VERSION ""

NS_ :

BU_: EBCM EON CAM RADAR PCM EPS VSA SCM BDY XXX EPB

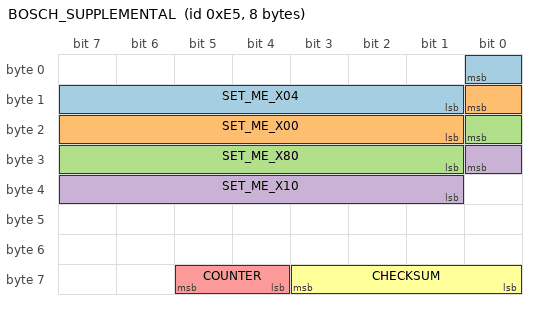
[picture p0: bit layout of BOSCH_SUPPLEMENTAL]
BO_ 229 BOSCH_SUPPLEMENTAL: 8 XXX
 SG_ SET_ME_X04 : 0|8@0+ (1,0) [0|255] "" XXX
 SG_ SET_ME_X00 : 8|8@0+ (1,0) [0|255] "" XXX
 SG_ SET_ME_X80 : 16|8@0+ (1,0) [0|255] "" XXX
 SG_ SET_ME_X10 : 24|8@0+ (1,0) [0|255] "" XXX
 SG_ COUNTER : 61|2@0+ (1,0) [0|3] "" XXX
 SG_ CHECKSUM : 59|4@0+ (1,0) [0|15] "" XXX

BO_ 513 SOMETHING: 8 XXX
 SG_ FULL : 7|63@0+ (1,0) [0|268435455] "" XXX

BO_ 576 CUR_LANE_LEFT_1: 8 XXX
 SG_ FULL : 7|63@0+ (1,0) [0|268435455] "" XXX
 SG_ PARM_1 : 6|11@0- (1,0) [-1023|1023] "" XXX
 SG_ PARM_2 : 22|11@0- (1,0) [-1023|1023] "" XXX
 SG_ PARM_3 : 39|9@0+ (1,0) [0|511] "" XXX
 SG_ PARM_4 : 46|7@0+ (1,0) [0|127] "" XXX
 SG_ PARM_5 : 54|7@0+ (1,0) [0|127] "" XXX
 SG_ FRAME_ID : 11|4@0+ (1,0) [0|15] "" XXX

BO_ 577 CUR_LANE_LEFT_2: 8 XXX
 SG_ FULL : 7|63@0+ (1,0) [0|268435455] "" XXX
 SG_ PARM_6 : 3|8@0+ (1,0) [0|255] "" XXX
 SG_ PARM_7 : 22|11@0- (1,0) [-1023|1023] "" XXX
 SG_ PARM_8 : 24|4@0+ (1,0) [0|15] "" XXX
 SG_ PARM_11 : 27|4@0+ (1,0) [0|15] "" XXX
 SG_ PARM_12 : 12|4@0+ (1,0) [0|15] "" XXX
 SG_ PARM_13 : 40|4@0+ (1,0) [0|15] "" XXX
 SG_ PARM_9 : 38|11@0- (1,0) [-1023|1023] "" XXX
 SG_ PARM_10 : 54|7@0- (1,0) [-63|63] "" XXX
 SG_ DASHED_LINE : 14|1@0+ (1,0) [0|1] "" XXX
 SG_ SOLID_LINE : 13|1@0+ (1,0) [0|1] "" XXX
 SG_ FRAME_ID : 7|4@0+ (1,0) [0|15] "" XXX

BO_ 579 CUR_LANE_RIGHT_1: 8 XXX
 SG_ FULL : 7|63@0+ (1,0) [0|268435455] "" XXX
 SG_ PARM_1 : 6|11@0- (1,0) [-1023|1023] "" XXX
 SG_ PARM_2 : 22|11@0- (1,0) [-1023|1023] "" XXX
 SG_ PARM_3 : 39|9@0+ (1,0) [0|511] "" XXX
 SG_ PARM_4 : 46|7@0+ (1,0) [0|127] "" XXX
 SG_ PARM_5 : 54|7@0+ (1,0) [0|127] "" XXX
 SG_ FRAME_ID : 11|4@0+ (1,0) [0|15] "" XXX

BO_ 580 CUR_LANE_RIGHT_2: 8 XXX
 SG_ FULL : 7|63@0+ (1,0) [0|268435455] "" XXX
 SG_ PARM_6 : 3|8@0+ (1,0) [0|255] "" XXX
 SG_ PARM_7 : 22|11@0- (1,0) [-1023|1023] "" XXX
 SG_ PARM_8 : 24|4@0+ (1,0) [0|15] "" XXX
 SG_ PARM_11 : 27|4@0+ (1,0) [0|15] "" XXX
 SG_ PARM_12 : 12|4@0+ (1,0) [0|15] "" XXX
 SG_ PARM_13 : 40|4@0+ (1,0) [0|15] "" XXX
 SG_ PARM_9 : 38|11@0- (1,0) [-1023|1023] "" XXX
 SG_ PARM_10 : 54|7@0- (1,0) [-63|63] "" XXX
 SG_ DASHED_LINE : 14|1@0+ (1,0) [0|1] "" XXX
 SG_ SOLID_LINE : 13|1@0+ (1,0) [0|1] "" XXX
 SG_ FRAME_ID : 7|4@0+ (1,0) [0|15] "" XXX

BO_ 582 ADJ_LANE_LEFT_1: 8 XXX
 SG_ FULL : 7|63@0+ (1,0) [0|268435455] "" XXX
 SG_ PARM_1 : 6|11@0- (1,0) [-1023|1023] "" XXX
 SG_ PARM_2 : 22|11@0- (1,0) [-1023|1023] "" XXX
 SG_ PARM_3 : 39|9@0+ (1,0) [0|511] "" XXX
 SG_ PARM_4 : 46|7@0+ (1,0) [0|127] "" XXX
 SG_ PARM_5 : 54|7@0+ (1,0) [0|127] "" XXX
 SG_ FRAME_ID : 11|4@0+ (1,0) [0|15] "" XXX

BO_ 583 ADJ_LANE_LEFT_2: 8 XXX
 SG_ FULL : 7|63@0+ (1,0) [0|268435455] "" XXX
 SG_ PARM_6 : 3|8@0+ (1,0) [0|255] "" XXX
 SG_ PARM_7 : 22|11@0- (1,0) [-1023|1023] "" XXX
 SG_ PARM_8 : 24|4@0+ (1,0) [0|15] "" XXX
 SG_ PARM_11 : 27|4@0+ (1,0) [0|15] "" XXX
 SG_ PARM_12 : 12|4@0+ (1,0) [0|15] "" XXX
 SG_ PARM_13 : 40|4@0+ (1,0) [0|15] "" XXX
 SG_ PARM_9 : 38|11@0- (1,0) [-1023|1023] "" XXX
 SG_ PARM_10 : 54|7@0- (1,0) [-63|63] "" XXX
 SG_ DASHED_LINE : 14|1@0+ (1,0) [0|1] "" XXX
 SG_ SOLID_LINE : 13|1@0+ (1,0) [0|1] "" XXX
 SG_ FRAME_ID : 7|4@0+ (1,0) [0|15] "" XXX

BO_ 585 ADJ_LANE_RIGHT_1: 8 XXX
 SG_ FULL : 7|63@0+ (1,0) [0|268435455] "" XXX
 SG_ PARM_1 : 6|11@0- (1,0) [-1023|1023] "" XXX
 SG_ PARM_2 : 22|11@0- (1,0) [-1023|1023] "" XXX
 SG_ PARM_3 : 39|9@0+ (1,0) [0|511] "" XXX
 SG_ PARM_4 : 46|7@0+ (1,0) [0|127] "" XXX
 SG_ PARM_5 : 54|7@0+ (1,0) [0|127] "" XXX
 SG_ FRAME_ID : 11|4@0+ (1,0) [0|15] "" XXX

BO_ 586 ADJ_LANE_RIGHT_2: 8 XXX
 SG_ FULL : 7|63@0+ (1,0) [0|268435455] "" XXX
 SG_ PARM_6 : 3|8@0+ (1,0) [0|255] "" XXX
 SG_ PARM_7 : 22|11@0- (1,0) [-1023|1023] "" XXX
 SG_ PARM_8 : 24|4@0+ (1,0) [0|15] "" XXX
 SG_ PARM_11 : 27|4@0+ (1,0) [0|15] "" XXX
 SG_ PARM_12 : 12|4@0+ (1,0) [0|15] "" XXX
 SG_ PARM_13 : 40|4@0+ (1,0) [0|15] "" XXX
 SG_ PARM_9 : 38|11@0- (1,0) [-1023|1023] "" XXX
 SG_ PARM_10 : 54|7@0- (1,0) [-63|63] "" XXX
 SG_ DASHED_LINE : 14|1@0+ (1,0) [0|1] "" XXX
 SG_ SOLID_LINE : 13|1@0+ (1,0) [0|1] "" XXX
 SG_ FRAME_ID : 7|4@0+ (1,0) [0|15] "" XXX

BO_ 640 OBJECT_A1: 8 XXX
 SG_ FULL : 7|63@0+ (1,0) [0|268435455] "" XXX
 SG_ CHECKSUM : 56|4@1+ (1,0) [0|15] "" XXX
 SG_ COUNTER : 60|2@1+ (1,0) [0|15] "" XXX
 SG_ CLOSING_SPEED : 6|7@0- (1,0) [-127|127] "" XXX
 SG_ PARM_1 : 15|8@0+ (1,0) [0|1] "" XXX
 SG_ DISTANCE : 22|11@0+ (1,0) [0|8191] "" XXX
 SG_ FRAME_ID : 27|4@0+ (1,0) [0|1] "" XXX
 SG_ OFFSET : 38|10@0- (1,0) [-1023|1023] "" XXX
 SG_ PARM_2 : 44|15@0+ (1,0) [0|31] "" XXX

BO_ 641 OBJECT_A2: 8 XXX
 SG_ FULL : 7|63@0+ (1,0) [0|268435455] "" XXX

BO_ 642 OBJECT_A3: 8 XXX
 SG_ FULL : 7|63@0+ (1,0) [0|268435455] "" XXX

BO_ 643 OBJECT_A4: 8 XXX
 SG_ FULL : 7|63@0+ (1,0) [0|268435455] "" XXX

BO_ 644 OBJECT_A5: 8 XXX
 SG_ FULL : 7|63@0+ (1,0) [0|268435455] "" XXX

BO_ 645 OBJECT_A6: 8 XXX
 SG_ FULL : 7|63@0+ (1,0) [0|268435455] "" XXX

BO_ 646 OBJECT_A7: 8 XXX
 SG_ FULL : 7|63@0+ (1,0) [0|268435455] "" XXX

BO_ 647 OBJECT_A8: 8 XXX
 SG_ FULL : 7|63@0+ (1,0) [0|268435455] "" XXX

BO_ 648 OBJECT_A9: 8 XXX
 SG_ FULL : 7|63@0+ (1,0) [0|268435455] "" XXX

BO_ 649 OBJECT_A10: 8 XXX
 SG_ FULL : 7|63@0+ (1,0) [0|268435455] "" XXX

BO_ 650 OBJECT_A11: 8 XXX
 SG_ FULL : 7|63@0+ (1,0) [0|268435455] "" XXX

BO_ 651 OBJECT_A12: 8 XXX
 SG_ FULL : 7|63@0+ (1,0) [0|268435455] "" XXX

BO_ 652 OBJECT_A13: 8 XXX
 SG_ FULL : 7|63@0+ (1,0) [0|268435455] "" XXX

BO_ 653 OBJECT_A14: 8 XXX
 SG_ FULL : 7|63@0+ (1,0) [0|268435455] "" XXX

BO_ 654 OBJECT_A15: 8 XXX
 SG_ FULL : 7|63@0+ (1,0) [0|268435455] "" XXX

BO_ 655 OBJECT_A16: 8 XXX
 SG_ FULL : 7|63@0+ (1,0) [0|268435455] "" XXX

BO_ 656 OBJECT_A17: 8 XXX
 SG_ FULL : 7|63@0+ (1,0) [0|268435455] "" XXX

BO_ 657 OBJECT_A18: 8 XXX
 SG_ FULL : 7|63@0+ (1,0) [0|268435455] "" XXX

BO_ 658 OBJECT_A19: 8 XXX
 SG_ FULL : 7|63@0+ (1,0) [0|268435455] "" XXX

BO_ 659 OBJECT_A20: 8 XXX
 SG_ FULL : 7|63@0+ (1,0) [0|268435455] "" XXX

BO_ 660 OBJECT_A21: 8 XXX
 SG_ FULL : 7|63@0+ (1,0) [0|268435455] "" XXX

BO_ 661 OBJECT_A22: 8 XXX
 SG_ FULL : 7|63@0+ (1,0) [0|268435455] "" XXX

BO_ 662 OBJECT_A23: 8 XXX
 SG_ FULL : 7|63@0+ (1,0) [0|268435455] "" XXX

BO_ 663 OBJECT_A24: 8 XXX
 SG_ FULL : 7|63@0+ (1,0) [0|268435455] "" XXX

BO_ 712 OBJECT_B1: 8 XXX
 SG_ FULL : 7|63@0+ (1,0) [0|268435455] "" XXX

BO_ 713 OBJECT_B2: 8 XXX
 SG_ FULL : 7|63@0+ (1,0) [0|268435455] "" XXX

BO_ 714 OBJECT_B3: 8 XXX
 SG_ FULL : 7|63@0+ (1,0) [0|268435455] "" XXX

BO_ 715 OBJECT_B4: 8 XXX
 SG_ FULL : 7|63@0+ (1,0) [0|268435455] "" XXX

BO_ 716 OBJECT_B5: 8 XXX
 SG_ FULL : 7|63@0+ (1,0) [0|268435455] "" XXX

BO_ 717 OBJECT_B6: 8 XXX
 SG_ FULL : 7|63@0+ (1,0) [0|268435455] "" XXX

BO_ 718 OBJECT_B7: 8 XXX
 SG_ FULL : 7|63@0+ (1,0) [0|268435455] "" XXX

BO_ 719 OBJECT_B8: 8 XXX
 SG_ FULL : 7|63@0+ (1,0) [0|268435455] "" XXX

BO_ 720 OBJECT_B9: 8 XXX
 SG_ FULL : 7|63@0+ (1,0) [0|268435455] "" XXX

BO_ 721 OBJECT_B10: 8 XXX
 SG_ FULL : 7|63@0+ (1,0) [0|268435455] "" XXX

BO_ 722 OBJECT_B11: 8 XXX
 SG_ FULL : 7|63@0+ (1,0) [0|268435455] "" XXX

BO_ 723 OBJECT_B12: 8 XXX
 SG_ FULL : 7|63@0+ (1,0) [0|268435455] "" XXX

BO_ 724 OBJECT_B13: 8 XXX
 SG_ FULL : 7|63@0+ (1,0) [0|268435455] "" XXX

BO_ 725 OBJECT_B14: 8 XXX
 SG_ FULL : 7|63@0+ (1,0) [0|268435455] "" XXX

BO_ 726 OBJECT_B15: 8 XXX
 SG_ FULL : 7|63@0+ (1,0) [0|268435455] "" XXX

BO_ 727 OBJECT_B16: 8 XXX
 SG_ FULL : 7|63@0+ (1,0) [0|268435455] "" XXX

BO_ 728 OBJECT_B17: 8 XXX
 SG_ FULL : 7|63@0+ (1,0) [0|268435455] "" XXX

BO_ 729 OBJECT_B18: 8 XXX
 SG_ FULL : 7|63@0+ (1,0) [0|268435455] "" XXX

BO_ 730 OBJECT_B19: 8 XXX
 SG_ FULL : 7|63@0+ (1,0) [0|268435455] "" XXX

BO_ 731 OBJECT_B20: 8 XXX
 SG_ FULL : 7|63@0+ (1,0) [0|268435455] "" XXX

BO_ 732 OBJECT_B21: 8 XXX
 SG_ FULL : 7|63@0+ (1,0) [0|268435455] "" XXX

BO_ 733 OBJECT_B22: 8 XXX
 SG_ FULL : 7|63@0+ (1,0) [0|268435455] "" XXX

BO_ 734 OBJECT_B23: 8 XXX
 SG_ FULL : 7|63@0+ (1,0) [0|268435455] "" XXX

BO_ 735 OBJECT_B24: 8 XXX
 SG_ FULL : 7|63@0+ (1,0) [0|268435455] "" XXX

BO_ 736 OBJECT_B25: 8 XXX
 SG_ FULL : 7|63@0+ (1,0) [0|268435455] "" XXX

BO_ 737 OBJECT_B26: 8 XXX
 SG_ FULL : 7|63@0+ (1,0) [0|268435455] "" XXX

BO_ 738 OBJECT_B27: 8 XXX
 SG_ FULL : 7|63@0+ (1,0) [0|268435455] "" XXX

BO_ 739 OBJECT_B28: 8 XXX
 SG_ FULL : 7|63@0+ (1,0) [0|268435455] "" XXX

BO_ 740 OBJECT_B29: 8 XXX
 SG_ FULL : 7|63@0+ (1,0) [0|268435455] "" XXX

BO_ 741 OBJECT_B30: 8 XXX
 SG_ FULL : 7|63@0+ (1,0) [0|268435455] "" XXX

BO_ 742 OBJECT_B31: 8 XXX
 SG_ FULL : 7|63@0+ (1,0) [0|268435455] "" XXX

BO_ 743 OBJECT_B32: 8 XXX
 SG_ FULL : 7|63@0+ (1,0) [0|268435455] "" XXX

BO_ 744 OBJECT_B33: 8 XXX
 SG_ FULL : 7|63@0+ (1,0) [0|268435455] "" XXX

BO_ 745 OBJECT_B34: 8 XXX
 SG_ FULL : 7|63@0+ (1,0) [0|268435455] "" XXX

BO_ 746 OBJECT_B35: 8 XXX
 SG_ FULL : 7|63@0+ (1,0) [0|268435455] "" XXX

BO_ 747 OBJECT_B36: 8 XXX
 SG_ FULL : 7|63@0+ (1,0) [0|268435455] "" XXX

BO_ 748 OBJECT_B37: 8 XXX
 SG_ FULL : 7|63@0+ (1,0) [0|268435455] "" XXX

BO_ 749 OBJECT_B38: 8 XXX
 SG_ FULL : 7|63@0+ (1,0) [0|268435455] "" XXX

BO_ 750 OBJECT_B39: 8 XXX
 SG_ FULL : 7|63@0+ (1,0) [0|268435455] "" XXX

BO_ 751 OBJECT_B40: 8 XXX
 SG_ FULL : 7|63@0+ (1,0) [0|268435455] "" XXX

BO_ 752 OBJECT_B41: 8 XXX
 SG_ FULL : 7|63@0+ (1,0) [0|268435455] "" XXX

BO_ 753 OBJECT_B42: 8 XXX
 SG_ FULL : 7|63@0+ (1,0) [0|268435455] "" XXX

BO_ 754 OBJECT_B43: 8 XXX
 SG_ FULL : 7|63@0+ (1,0) [0|268435455] "" XXX

BO_ 755 OBJECT_B44: 8 XXX
 SG_ FULL : 7|63@0+ (1,0) [0|268435455] "" XXX

BO_ 756 OBJECT_B45: 8 XXX
 SG_ FULL : 7|63@0+ (1,0) [0|268435455] "" XXX

BO_ 757 OBJECT_B46: 8 XXX
 SG_ FULL : 7|63@0+ (1,0) [0|268435455] "" XXX

BO_ 758 OBJECT_B47: 8 XXX
 SG_ FULL : 7|63@0+ (1,0) [0|268435455] "" XXX

BO_ 759 OBJECT_B48: 8 XXX
 SG_ FULL : 7|63@0+ (1,0) [0|268435455] "" XXX

BO_ 760 OBJECT_B49: 8 XXX
 SG_ FULL : 7|63@0+ (1,0) [0|268435455] "" XXX

BO_ 761 OBJECT_B50: 8 XXX
 SG_ FULL : 7|63@0+ (1,0) [0|268435455] "" XXX

BO_ 762 OBJECT_B51: 8 XXX
 SG_ FULL : 7|63@0+ (1,0) [0|268435455] "" XXX

BO_ 763 OBJECT_B52: 8 XXX
 SG_ FULL : 7|63@0+ (1,0) [0|268435455] "" XXX

BO_ 764 OBJECT_B53: 8 XXX
 SG_ FULL : 7|63@0+ (1,0) [0|268435455] "" XXX

BO_ 765 OBJECT_B54: 8 XXX
 SG_ FULL : 7|63@0+ (1,0) [0|268435455] "" XXX

BO_ 766 OBJECT_B55: 8 XXX
 SG_ FULL : 7|63@0+ (1,0) [0|268435455] "" XXX

BO_ 767 OBJECT_B56: 8 XXX
 SG_ FULL : 7|63@0+ (1,0) [0|268435455] "" XXX
